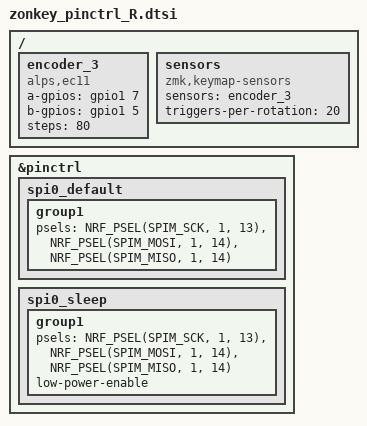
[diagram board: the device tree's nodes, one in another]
&pinctrl {
    spi0_default: spi0_default {
        group1 {
            psels = <NRF_PSEL(SPIM_SCK, 1, 13)>,
                    <NRF_PSEL(SPIM_MOSI, 1, 14)>,
                    <NRF_PSEL(SPIM_MISO, 1, 14)>;
        };
    };

    spi0_sleep: spi0_sleep {
        group1 {
            psels = <NRF_PSEL(SPIM_SCK, 1, 13)>,
                    <NRF_PSEL(SPIM_MOSI, 1, 14)>,
                    <NRF_PSEL(SPIM_MISO, 1, 14)>;
            low-power-enable;
        };
    };
};
/ {
    encoder_3: encoder_3 {
        compatible = "alps,ec11";
        a-gpios = <&gpio1 7 (GPIO_ACTIVE_HIGH | GPIO_PULL_UP)>;
        b-gpios = <&gpio1 5 (GPIO_ACTIVE_HIGH | GPIO_PULL_UP)>;
        steps = <80>;
        status = "okay";
    };

    sensors: sensors {
        compatible = "zmk,keymap-sensors";
        sensors = <&encoder_3>;
        triggers-per-rotation = <20>;
    };
};
